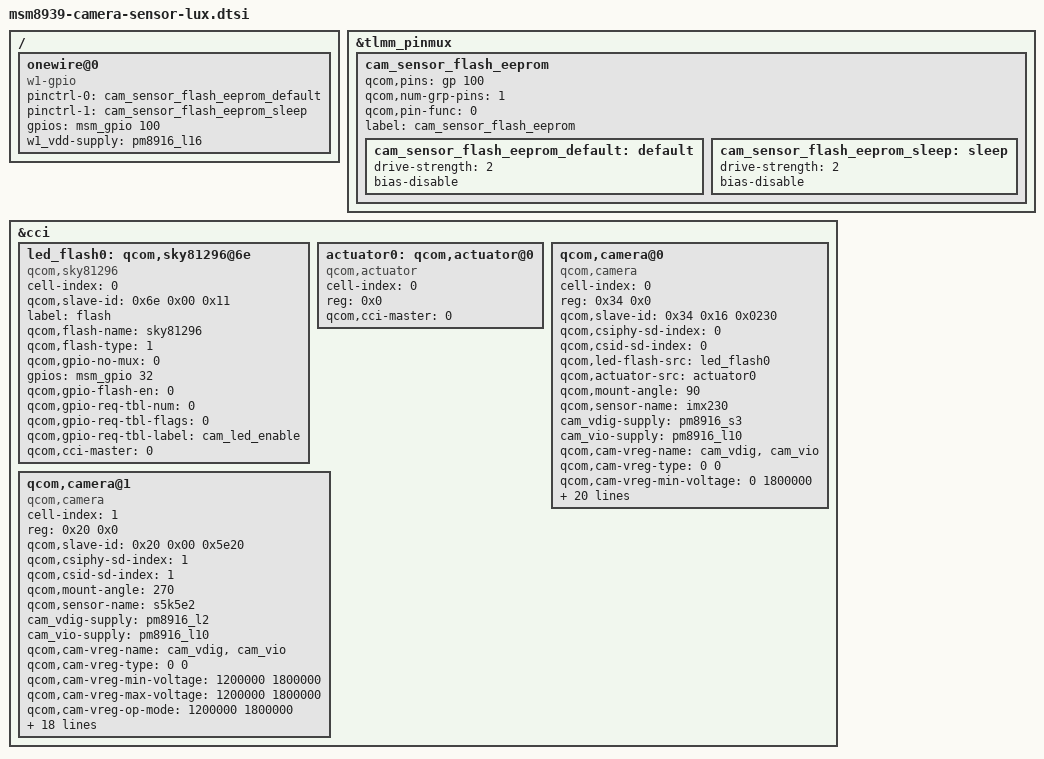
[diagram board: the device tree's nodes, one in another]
/*
 * Copyright (c) 2015, The Linux Foundation. All rights reserved.
 *
 * This program is free software; you can redistribute it and/or modify
 * it under the terms of the GNU General Public License version 2 and
 * only version 2 as published by the Free Software Foundation.
 *
 * This program is distributed in the hope that it will be useful,
 * but WITHOUT ANY WARRANTY; without even the implied warranty of
 * MERCHANTABILITY or FITNESS FOR A PARTICULAR PURPOSE.  See the
 * GNU General Public License for more details.
 */

&tlmm_pinmux {
	cam_sensor_flash_eeprom {
		/* FLASH_EEPROM_DATA */
		qcom,pins = <&gp 100>;
		qcom,num-grp-pins = <1>;
		qcom,pin-func = <0>;
		label = "cam_sensor_flash_eeprom";
		/* active state */
		cam_sensor_flash_eeprom_default: default {
			drive-strength = <2>;
			bias-disable;
		};
		/*suspended state */
		cam_sensor_flash_eeprom_sleep: sleep {
			drive-strength = <2>;
			bias-disable;
		};
	};
};

/ {
	/* Flash EEPROM */
	onewire@0 {
		compatible = "w1-gpio";
		pinctrl-names = "default", "suspend";
		pinctrl-0 = <&cam_sensor_flash_eeprom_default>;
		pinctrl-1 = <&cam_sensor_flash_eeprom_sleep>;
		gpios = <&msm_gpio 100 0>;
		w1_vdd-supply = <&pm8916_l16>;
	};
};

&cci {
	/* skyworks sky81296 flash LED driver*/
	led_flash0: qcom,sky81296@6e {
		cell-index = <0>;
		qcom,slave-id = <0x6e 0x00 0x11>;
		compatible = "qcom,sky81296";
		label = "flash";
		qcom,flash-name = "sky81296";
		qcom,flash-type = <1>;
		qcom,gpio-no-mux = <0>;
		gpios = <&msm_gpio 32 0>;
		qcom,gpio-flash-en = <0>;
		qcom,gpio-req-tbl-num = <0>;
		qcom,gpio-req-tbl-flags = <0>;
		qcom,gpio-req-tbl-label = "cam_led_enable";
		qcom,cci-master = <0>;
	};

	actuator0: qcom,actuator@0 {
		cell-index = <0>;
		reg = <0x0>;
		compatible = "qcom,actuator";
		qcom,cci-master = <0>;
	};

	qcom,camera@0 {
		cell-index = <0>;
		compatible = "qcom,camera";
		reg = <0x34 0x0>;
		qcom,slave-id = <0x34 0x16 0x0230>;
		qcom,csiphy-sd-index = <0>;
		qcom,csid-sd-index = <0>;
		qcom,led-flash-src = <&led_flash0>;
		qcom,actuator-src = <&actuator0>;
		qcom,mount-angle = <90>;
		qcom,sensor-name = "imx230";
		cam_vdig-supply = <&pm8916_s3>;
		cam_vio-supply = <&pm8916_l10>;
		qcom,cam-vreg-name = "cam_vdig","cam_vio";
		qcom,cam-vreg-type = <0 0>;
		qcom,cam-vreg-min-voltage = <0 1800000>;
		qcom,cam-vreg-max-voltage = <0 1800000>;
		qcom,cam-vreg-op-mode = <0 1800000>;
		pinctrl-names = "cam_default", "cam_suspend";
		pinctrl-0 = <&cam_sensor_mclk0_default
			&cam_sensor_rear_default>;
		pinctrl-1 = <&cam_sensor_mclk0_sleep &cam_sensor_rear_sleep>;
		gpios = <&msm_gpio 26 0>,
			<&msm_gpio 33 0>,
			<&msm_gpio 35 0>;
		qcom,gpio-vana = <1>;
		qcom,gpio-reset = <2>;
		qcom,gpio-req-tbl-num = <0 1 2>;
		qcom,gpio-req-tbl-flags = <0 0 0>;
		qcom,gpio-req-tbl-label = "CAMR_MCLK",
					"CAMR_VANA",
					"CAMR_RESET";
		qcom,csi-lane-assign = <0x4320>;
		qcom,csi-lane-mask = <0x1f>;
		qcom,sensor-position = <0>;
		qcom,sensor-mode = <0>;
		qcom,cci-master = <0>;
		clocks = <&clock_gcc clk_mclk0_clk_src>,
			<&clock_gcc clk_gcc_camss_mclk0_clk>;
		clock-names = "cam_src_clk", "cam_clk";

		status = "ok";
	};

	qcom,camera@1 {
		cell-index = <1>;
		compatible = "qcom,camera";
		reg = <0x20 0x0>;
		qcom,slave-id = <0x20 0x00 0x5e20>;
		qcom,csiphy-sd-index = <1>;
		qcom,csid-sd-index = <1>;
		qcom,mount-angle = <270>;
		qcom,sensor-name = "s5k5e2";
		cam_vdig-supply = <&pm8916_l2>;
		cam_vio-supply = <&pm8916_l10>;
		qcom,cam-vreg-name = "cam_vdig","cam_vio";
		qcom,cam-vreg-type = <0 0>;
		qcom,cam-vreg-min-voltage = <1200000 1800000>;
		qcom,cam-vreg-max-voltage = <1200000 1800000>;
		qcom,cam-vreg-op-mode = <1200000 1800000>;
		pinctrl-names = "cam_default", "cam_suspend";
		pinctrl-0 = <&cam_sensor_mclk1_default
			&cam_sensor_front_default>;
		pinctrl-1 = <&cam_sensor_mclk1_sleep &cam_sensor_front_sleep>;
		gpios = <&msm_gpio 27 0>,
			<&msm_gpio 79 0>,
			<&msm_gpio 28 0>;
		qcom,gpio-vana = <1>;
		qcom,gpio-reset = <2>;
		qcom,gpio-req-tbl-num = <0 1 2>;
		qcom,gpio-req-tbl-flags = <0 0 0>;
		qcom,gpio-req-tbl-label = "CAMF_MCLK",
					"CAMF_VANA",
					"CAMF_RESET";
		qcom,csi-lane-assign = <0x4320>;
		qcom,csi-lane-mask = <0x7>;
		qcom,sensor-position = <1>;
		qcom,sensor-mode = <1>;
		qcom,cci-master = <0>;
		clocks = <&clock_gcc clk_mclk1_clk_src>,
			<&clock_gcc clk_gcc_camss_mclk1_clk>;
		clock-names = "cam_src_clk", "cam_clk";

		status = "ok";
	};
};
